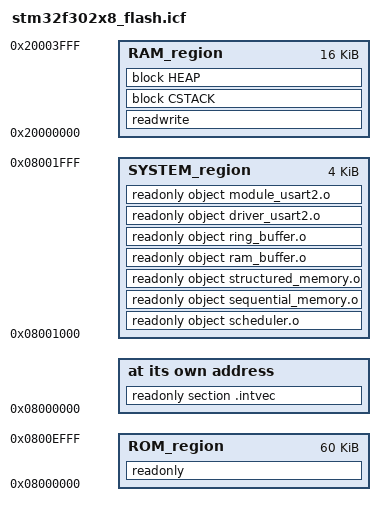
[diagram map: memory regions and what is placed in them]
/*###ICF### Section handled by ICF editor, don't touch! ****/
/*-Editor annotation file-*/
/* IcfEditorFile="$TOOLKIT_DIR$\config\ide\IcfEditor\cortex_v1_0.xml" */
/*-Specials-*/
define symbol __ICFEDIT_intvec_start__ = 0x08000000;
/*-Memory Regions-*/
define symbol __ICFEDIT_region_ROM_start__ = 0x08000000;
define symbol __ICFEDIT_region_ROM_end__   = 0x0800EFFF;
define symbol __ICFEDIT_region_SETTING_start__ = 0x0800F000;    /**reserve 4Kbyte for setting storage **/
define symbol __ICFEDIT_region_SETTING_end__   = 0x0800FFFF;        
define symbol __ICFEDIT_region_RAM_start__ = 0x20000000;
define symbol __ICFEDIT_region_RAM_end__   = 0x20003FFF;
/*-Sizes-*/
define symbol __ICFEDIT_size_cstack__ = 0x400;
define symbol __ICFEDIT_size_heap__ = 0x1000;
/**** End of ICF editor section. ###ICF###*/


define memory mem with size = 4G;
define region ROM_region      = mem:[from __ICFEDIT_region_ROM_start__   to __ICFEDIT_region_ROM_end__];
define region SYSTEM_region   = mem:[from 0x08001000 to 0x08001FFF];
define region RAM_region      = mem:[from __ICFEDIT_region_RAM_start__   to __ICFEDIT_region_RAM_end__];

define block CSTACK    with alignment = 8, size = __ICFEDIT_size_cstack__   { };
define block HEAP      with alignment = 8, size = __ICFEDIT_size_heap__     { };

initialize by copy { readwrite };
do not initialize  { section .noinit };

place at address mem:__ICFEDIT_intvec_start__ { readonly section .intvec };

place in ROM_region   { readonly };
place in SYSTEM_region { readonly object scheduler.o, 
                         readonly object sequential_memory.o, 
                         readonly object structured_memory.o, 
                         readonly object ram_buffer.o,
                         readonly object ring_buffer.o,
                         readonly object driver_usart2.o,
                         readonly object module_usart2.o
                         };
place in RAM_region   { readwrite,
                        block CSTACK, block HEAP };
